# STM32U5Gx register map
File version: 1.0
CPU: CM33 r0p1, little endian, MPU, FPU, 4 interrupt priority bits
Registers are 32-bit, read-write, reset 0x0 unless marked. A register's access mark holds for its fields unless they carry their own. Offsets are from the block's base; [hi:lo] are bit positions; {n}, {i} and the like mark numbered series.

## RCC (part 3 of 4) — Reset and clock control
Base 0x46020C00
Same registers: SEC_RCC 0x56020C00
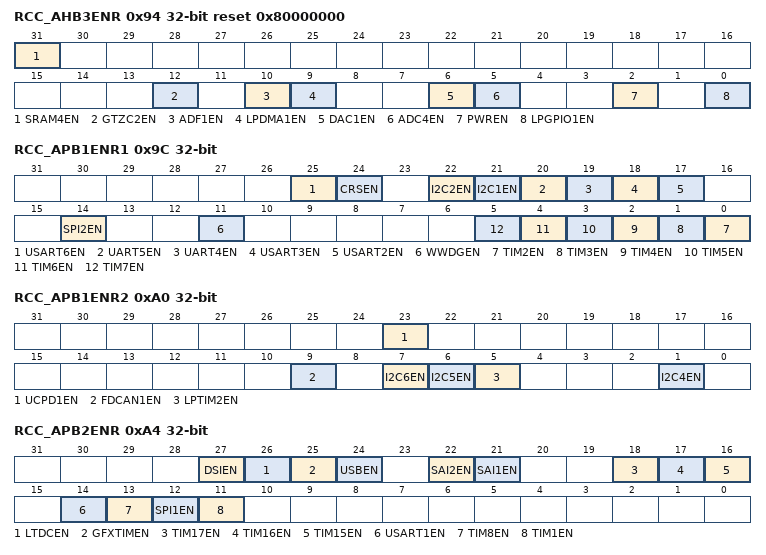
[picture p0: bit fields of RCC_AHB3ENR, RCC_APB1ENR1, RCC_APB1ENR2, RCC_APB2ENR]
0x94 RCC_AHB3ENR reset 0x80000000 — RCC AHB3 peripheral clock enable register
  [31] SRAM4EN — SRAM4 clock enable This bit is set and reset by software.
    0=SRAM4 clock disabled; 1=SRAM4 clock enabled
  [12] GTZC2EN — GTZC2 clock enable This bit is set and cleared by software.
    0=GTZC2 clock disabled; 1=GTZC2 clock enabled
  [10] ADF1EN — ADF1 clock enable This bit is set and cleared by software.
    0=ADF1 clock disabled; 1=ADF1 clock enabled
  [9] LPDMA1EN — LPDMA1 clock enable This bit is set and cleared by software.
    0=LPDMA1 clock disabled; 1=LPDMA1 clock enabled
  [6] DAC1EN — DAC1 clock enable This bit is set and cleared by software.
    0=DAC1 clock disabled; 1=DAC1 clock enabled
  [5] ADC4EN — ADC4 clock enable This bit is set and cleared by software.
    0=ADC4 clock disabled; 1=ADC4 clock enabled
  [2] PWREN — PWR clock enable This bit is set and cleared by software.
    0=PWR clock disabled; 1=PWR clock enabled
  [0] LPGPIO1EN — LPGPIO1 enable This bit is set and cleared by software.
    0=LPGPIO1 clock disabled; 1=LPGPIO1 clock enabled
0x9C RCC_APB1ENR1 — RCC APB1 peripheral clock enable register 1
  [25] USART6EN — USART6 clock enable This bit is set and cleared by software. Note: This bit is only available on some devices in the STM32U5 Series. Refer to the device datasheet for availability of its associated peripheral. If not present, consider this bit as reserved and keep it at reset value.
    0=USART6 clock disabled; 1=USART6 clock enabled
  [24] CRSEN — CRS clock enable This bit is set and cleared by software.
    0=CRS clock disabled; 1=CRS clock enabled
  [22] I2C2EN — I2C2 clock enable This bit is set and cleared by software.
    0=I2C2 clock disabled; 1=I2C2 clock enabled
  [21] I2C1EN — I2C1 clock enable This bit is set and cleared by software.
    0=I2C1 clock disabled; 1=I2C1 clock enabled
  [20] UART5EN — UART5 clock enable This bit is set and cleared by software.
    0=UART5 clock disabled; 1=UART5 clock enabled
  [19] UART4EN — UART4 clock enable This bit is set and cleared by software.
    0=UART4 clock disabled; 1=UART4 clock enabled
  [18] USART3EN — USART3 clock enable This bit is set and cleared by software.
    0=USART3 clock disabled; 1=USART3 clock enabled
  [17] USART2EN — USART2 clock enable This bit is set and cleared by software. Note: This bit is only available on some devices in the STM32U5 Series. Refer to the device datasheet for availability of its associated peripheral. If not present, consider this bit as reserved and keep it at reset value.
    0=USART2 clock disabled; 1=USART2 clock enabled
  [14] SPI2EN — SPI2 clock enable This bit is set and cleared by software.
    0=SPI2 clock disabled; 1=SPI2 clock enabled
  [11] WWDGEN — WWDG clock enable This bit is set by software to enable the window watchdog clock. It is reset by hardware system reset. This bit can also be set by hardware if the WWDG_SW option bit is reset.
    0=WWDG clock disabled; 1=WWDG clock enabled
  [n-2] TIM{n}EN (n=2..7) — TIM{n} clock enable This bit is set and cleared by software.
    0=TIM{n} clock disabled; 1=TIM{n} clock enabled
0xA0 RCC_APB1ENR2 — RCC APB1 peripheral clock enable register 2
  [23] UCPD1EN — UCPD1 clock enable This bit is set and cleared by software. Note: This bit is only available on some devices in the STM32U5 Series. Refer to the device datasheet for availability of its associated peripheral. If not present, consider this bit as reserved and keep it at reset value.
    0=UCPD1 clock disabled; 1=UCPD1 clock enabled
  [9] FDCAN1EN — FDCAN1 clock enable This bit is set and cleared by software.
    0=FDCAN1 clock disabled; 1=FDCAN1 clock enabled
  [7] I2C6EN — I2C6 clock enable This bit is set and cleared by software. Note: This bit is only available on some devices in the STM32U5 Series. Refer to the device datasheet for availability of its associated peripheral. If not present, consider this bit as reserved and keep it at reset value.
    0=I2C6 clock disabled; 1=I2C6 clock enabled
  [6] I2C5EN — I2C5 clock enable This bit is set and cleared by software. Note: This bit is only available on some devices in the STM32U5 Series. Refer to the device datasheet for availability of its associated peripheral. If not present, consider this bit as reserved and keep it at reset value.
    0=I2C5 clock disabled; 1=I2C5 clock enabled
  [5] LPTIM2EN — LPTIM2 clock enable This bit is set and cleared by software.
    0=LPTIM2 clock disabled; 1=LPTIM2 clock enabled
  [1] I2C4EN — I2C4 clock enable This bit is set and cleared by software
    0=I2C4 clock disabled; 1=I2C4 clock enabled
0xA4 RCC_APB2ENR — RCC APB2 peripheral clock enable register
  [27] DSIEN — DSI clock enable This bit is set and cleared by software. Note: This bit is only available on some devices in the STM32U5 Series. Refer to the device datasheet for availability of its associated peripheral. If not present, consider this bit as reserved and keep it at reset value.
    0=DSI clock disabled; 1=DSI clock enabled
  [26] LTDCEN — LTDC clock enable This bit is set and cleared by software. Note: This bit is only available on some devices in the STM32U5 Series. Refer to the device datasheet for availability of its associated peripheral. If not present, consider this bit as reserved and keep it at reset value.
    0=LTDC clock disabled; 1=LTDC clock enabled
  [25] GFXTIMEN — GFXTIM clock enable This bit is set and cleared by software. Note: This bit is only available on some devices in the STM32U5 Series. Refer to the device datasheet for availability of its associated peripheral. If not present, consider this bit as reserved and keep it at reset value.
    0=GFXTIM clock disabled; 1=GFXTIM clock enabled
  [24] USBEN — USB clock enable This bit is set and cleared by software. Note: This bit is only available on some devices in the STM32U5 Series. Refer to the device datasheet for availability of its associated peripheral. If not present, consider this bit as reserved and keep it at reset value.
    0=USB clock disabled; 1=USB clock enabled
  [22] SAI2EN — SAI2 clock enable This bit is set and cleared by software. Note: This bit is only available on some devices in the STM32U5 Series. Refer to the device datasheet for availability of its associated peripheral. If not present, consider this bit as reserved and keep it at reset value.
    0=SAI2 clock disabled; 1=SAI2 clock enabled
  [21] SAI1EN — SAI1 clock enable This bit is set and cleared by software.
    0=SAI1 clock disabled; 1=SAI1 clock enabled
  [18] TIM17EN — TIM17 clock enable This bit is set and cleared by software.
    0=TIM17 clock disabled; 1=TIM17 clock enabled
  [17] TIM16EN — TIM16 clock enable This bit is set and cleared by software.
    0=TIM16 clock disabled; 1=TIM16 clock enabled
  [16] TIM15EN — TIM15 clock enable This bit is set and cleared by software.
    0=TIM15 clock disabled; 1=TIM15 clock enabled
  [14] USART1EN — USART1clock enable This bit is set and cleared by software.
    0=USART1 clock disabled; 1=USART1 clock enabled
  [13] TIM8EN — TIM8 clock enable This bit is set and cleared by software.
    0=TIM8 clock disabled; 1=TIM8 clock enabled
  [12] SPI1EN — SPI1 clock enable This bit is set and cleared by software.
    0=SPI1 clock disabled; 1=SPI1 clock enabled
  [11] TIM1EN — TIM1 clock enable This bit is set and cleared by software.
    0=TIM1 clock disabled; 1=TIM1 clock enabled
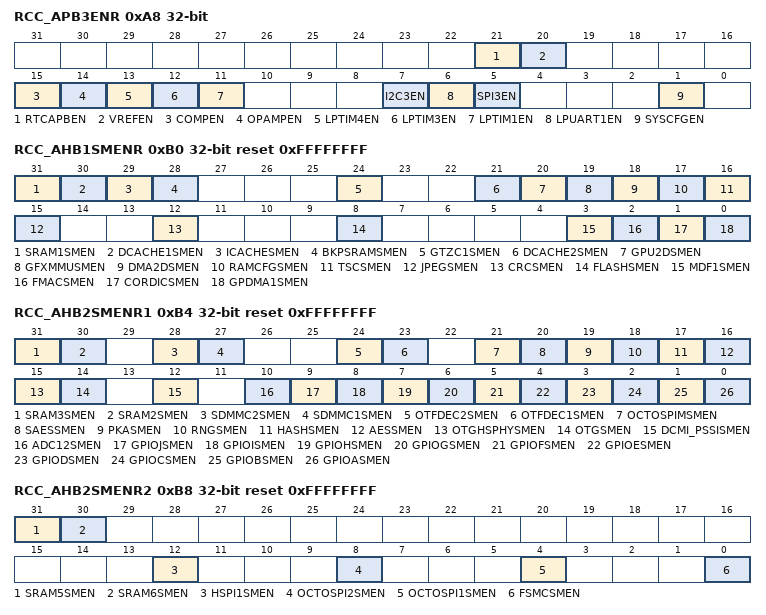
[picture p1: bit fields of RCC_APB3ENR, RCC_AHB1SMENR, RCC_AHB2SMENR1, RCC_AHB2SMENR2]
0xA8 RCC_APB3ENR — RCC APB3 peripheral clock enable register
  [21] RTCAPBEN — RTC and TAMP APB clock enable This bit is set and cleared by software.
    0=RTC and TAMP APB clock disabled; 1=RTC and TAMP APB clock enabled
  [20] VREFEN — VREFBUF clock enable This bit is set and cleared by software.
    0=VREFBUF clock disabled; 1=VREFBUF clock enabled
  [15] COMPEN — COMP clock enable This bit is set and cleared by software.
    0=COMP clock disabled; 1=COMP clock enabled
  [14] OPAMPEN — OPAMP clock enable This bit is set and cleared by software.
    0=OPAMP clock disabled; 1=OPAMP clock enabled
  [13] LPTIM4EN — LPTIM4 clock enable This bit is set and cleared by software.
    0=LPTIM4 clock disabled; 1=LPTIM4 clock enabled
  [12] LPTIM3EN — LPTIM3 clock enable This bit is set and cleared by software.
    0=LPTIM3 clock disabled; 1=LPTIM3 clock enabled
  [11] LPTIM1EN — LPTIM1 clock enable This bit is set and cleared by software.
    0=LPTIM1 clock disabled; 1=LPTIM1 clock enabled
  [7] I2C3EN — I2C3 clock enable This bit is set and cleared by software.
    0=I2C3 clock disabled; 1=I2C3 clock enabled
  [6] LPUART1EN — LPUART1 clock enable This bit is set and cleared by software.
    0=LPUART1 clock disabled; 1=LPUART1 clock enabled
  [5] SPI3EN — SPI3 clock enable This bit is set and cleared by software.
    0=SPI3 clock disabled; 1=SPI3 clock enabled
  [1] SYSCFGEN — SYSCFG clock enable This bit is set and cleared by software.
    0=SYSCFG clock disabled; 1=SYSCFG clock enabled
0xB0 RCC_AHB1SMENR reset 0xFFFFFFFF — RCC AHB1 peripheral clock enable in Sleep and Stop modes register
  [31] SRAM1SMEN — SRAM1 clock enable during Sleep and Stop modes This bit is set and cleared by software.
    0=SRAM1 clocks disabled by the clock gating during Sleep and Stop modes; 1=SRAM1 clocks enabled by the clock gating during Sleep and Stop modes
  [30] DCACHE1SMEN — DCACHE1 clock enable during Sleep and Stop modes This bit is set and cleared by software.
    0=DCACHE1 clocks disabled by the clock gating during Sleep and Stop modes; 1=DCACHE1 clocks enabled by the clock gating during Sleep and Stop modes
  [29] ICACHESMEN — ICACHE clock enable during Sleep and Stop modes This bit is set and cleared by software.
    0=ICACHE clocks disabled by the clock gating during Sleep and Stop modes; 1=ICACHE clocks enabled by the clock gating during Sleep and Stop modes
  [28] BKPSRAMSMEN — BKPSRAM clock enable during Sleep and Stop modes This bit is set and cleared by software
    0=BKPSRAM clocks disabled by the clock gating during Sleep and Stop modes; 1=BKPSRAM clocks enabled by the clock gating during Sleep and Stop modes
  [24] GTZC1SMEN — GTZC1 clock enable during Sleep and Stop modes This bit is set and cleared by software.
    0=GTZC1 clocks disabled by the clock gating during Sleep and Stop modes; 1=GTZC1 clocks enabled by the clock gating during Sleep and Stop modes
  [21] DCACHE2SMEN — DCACHE2 clock enable during Sleep and Stop modes This bit is set and cleared by software. Note: This bit is only available on some devices in the STM32U5 Series. Refer to the device datasheet for availability of its associated peripheral. If not present, consider this bit as reserved and keep it at reset value.
    0=DCACHE2 clocks disabled by the clock gating during Sleep and Stop modes; 1=DCACHE2 clocks enabled by the clock gating during Sleep and Stop modes
  [20] GPU2DSMEN — GPU2D clock enable during Sleep and Stop modes This bit is set and cleared by software. Note: This bit is only available on some devices in the STM32U5 Series. Refer to the device datasheet for availability of its associated peripheral. If not present, consider this bit as reserved and keep it at reset value.
    0=GPU2D clocks disabled by the clock gating during Sleep and Stop modes; 1=GPU2D clocks enabled by the clock gating during Sleep and Stop modes
  [19] GFXMMUSMEN — GFXMMU clock enable during Sleep and Stop modes This bit is set and cleared by software. Note: This bit is only available on some devices in the STM32U5 Series. Refer to the device datasheet for availability of its associated peripheral. If not present, consider this bit as reserved and keep it at reset value.
    0=GFXMMU clocks disabled by the clock gating during Sleep and Stop modes; 1=GFXMMU clocks enabled by the clock gating during Sleep and Stop modes
  [18] DMA2DSMEN — DMA2D clock enable during Sleep and Stop modes This bit is set and cleared by software. Note: This bit is only available on some devices in the STM32U5 Series. Refer to the device datasheet for availability of its associated peripheral. If not present, consider this bit as reserved and keep it at reset value.
    0=DMA2D clocks disabled by the clock gating during Sleep and Stop modes; 1=DMA2D clocks enabled by the clock gating during Sleep and Stop modes
  [17] RAMCFGSMEN — RAMCFG clock enable during Sleep and Stop modes This bit is set and cleared by software.
    0=RAMCFG clocks disabled by the clock gating during Sleep and Stop modes; 1=RAMCFG clocks enabled by the clock gating during Sleep and Stop modes
  [16] TSCSMEN — TSC clocks enable during Sleep and Stop modes This bit is set and cleared by software.
    0=TSC clocks disabled by the clock gating during Sleep and Stop modes; 1=TSC clocks enabled by the clock gating during Sleep and Stop modes
  [15] JPEGSMEN — JPEG clocks enable during Sleep and Stop modes This bit is set and cleared by software. Note: This bit is only available on some devices in the STM32U5 Series. Refer to the device datasheet for availability of its associated peripheral. If not present, consider this bit as reserved and keep it at reset value.
    0=JPEG clocks disabled by the clock gating during Sleep and Stop modes; 1=JPEG clocks enabled by the clock gating during Sleep and Stop modes
  [12] CRCSMEN — CRC clocks enable during Sleep and Stop modes This bit is set and cleared by software.
    0=CRC clocks disabled by the clock gating during Sleep and Stop modes; 1=CRC clocks enabled by the clock gating during Sleep and Stop modes
  [8] FLASHSMEN — FLASH clocks enable during Sleep and Stop modes This bit is set and cleared by software.
    0=FLASH clocks disabled by the clock gating during Sleep and Stop modes; 1=FLASH clocks enabled by the clock gating during Sleep and Stop modes
  [3] MDF1SMEN — MDF1 clocks enable during Sleep and Stop modes. This bit is set and cleared by software. Note: This bit must be set to allow the peripheral to wake up from Stop modes.
    0=MDF1 clocks disabled by the clock gating during Sleep and Stop modes; 1=MDF1 clocks enabled by the clock gating during Sleep and Stop modes
  [2] FMACSMEN — FMAC clocks enable during Sleep and Stop modes. This bit is set and cleared by software.
    0=FMAC clocks disabled by the clock gating during Sleep and Stop modes; 1=FMAC clocks enabled by the clock gating during Sleep and Stop modes
  [1] CORDICSMEN — CORDIC clocks enable during Sleep and Stop modes This bit is set and cleared by software during Sleep mode.
    0=CORDIC clocks disabled by the clock gating during Sleep and Stop modes; 1=CORDIC clocks enabled by the clock gating during Sleep and Stop modes
  [0] GPDMA1SMEN — GPDMA1 clocks enable during Sleep and Stop modes This bit is set and cleared by software. Note: This bit must be set to allow the peripheral to wake up from Stop modes.
    0=GPDMA1 clocks disabled by the clock gating during Sleep and Stop modes; 1=GPDMA1 clocks enabled by the clock gating during Sleep and Stop modes
0xB4 RCC_AHB2SMENR1 reset 0xFFFFFFFF — RCC AHB2 peripheral clock enable in Sleep and Stop modes register 1
  [31] SRAM3SMEN — SRAM3 clock enable during Sleep and Stop modes This bit is set and cleared by software. Note: This bit is only available on some devices in the STM32U5 Series. Refer to the device datasheet for availability of its associated peripheral. If not present, consider this bit as reserved and keep it at reset value.
    0=SRAM3 clocks disabled by the clock gating during Sleep and Stop modes; 1=SRAM3 clocks enabled by the clock gating during Sleep and Stop modes
  [30] SRAM2SMEN — SRAM2 clock enable during Sleep and Stop modes This bit is set and cleared by software.
    0=SRAM2 clocks disabled by the clock gating during Sleep and Stop modes; 1=SRAM2 clocks enabled by the clock gating during Sleep and Stop modes
  [28] SDMMC2SMEN — SDMMC2 clock enable during Sleep and Stop modes This bit is set and cleared by software. Note: This bit is only available on some devices in the STM32U5 Series. Refer to the device datasheet for availability of its associated peripheral. If not present, consider this bit as reserved and keep it at reset value.
    0=SDMMC2 clocks disabled by the clock gating during Sleep and Stop modes; 1=SDMMC2 clocks enabled by the clock gating during Sleep and Stop modes
  [27] SDMMC1SMEN — SDMMC1 clock enable during Sleep and Stop modes This bit is set and cleared by software.
    0=SDMMC1 clocks disabled by the clock gating during Sleep and Stop modes; 1=SDMMC1 clocks enabled by the clock gating during Sleep and Stop modes
  [24] OTFDEC2SMEN — OTFDEC2 clock enable during Sleep and Stop modes This bit is set and cleared by software. Note: This bit is only available on some devices in the STM32U5 Series. Refer to the device datasheet for availability of its associated peripheral. If not present, consider this bit as reserved and keep it at reset value.
    0=OTFDEC2 clocks disabled by the clock gating during Sleep and Stop modes; 1=OTFDEC2 clocks enabled by the clock gating during Sleep and Stop modes
  [23] OTFDEC1SMEN — OTFDEC1 clock enable during Sleep and Stop modes This bit is set and cleared by software. Note: This bit is only available on some devices in the STM32U5 Series. Refer to the device datasheet for availability of its associated peripheral. If not present, consider this bit as reserved and keep it at reset value.
    0=OTFDEC1 clocks disabled by the clock gating during Sleep and Stop modes; 1=OTFDEC1 clocks enabled by the clock gating during Sleep and Stop modes
  [21] OCTOSPIMSMEN — OCTOSPIM clock enable during Sleep and Stop modes This bit is set and cleared by software. Note: This bit is only available on some devices in the STM32U5 Series. Refer to the device datasheet for availability of its associated peripheral. If not present, consider this bit as reserved and keep it at reset value.
    0=OCTOSPIM clocks disabled by the clock gating during Sleep and Stop modes; 1=OCTOSPIM clocks enabled by the clock gating during Sleep and Stop modes
  [20] SAESSMEN — SAES accelerator clock enable during Sleep and Stop modes This bit is set and cleared by software. Note: This bit is only available on some devices in the STM32U5 Series. Refer to the device datasheet for availability of its associated peripheral. If not present, consider this bit as reserved and keep it at reset value.
    0=SAES clocks disabled by the clock gating during Sleep and Stop modes; 1=SAES clocks enabled by the clock gating during Sleep and Stop modes
  [19] PKASMEN — PKA clock enable during Sleep and Stop modes This bit is set and cleared by software. Note: This bit is only available on some devices in the STM32U5 Series. Refer to the device datasheet for availability of its associated peripheral. If not present, consider this bit as reserved and keep it at reset value.
    0=PKA clocks disabled by the clock gating during Sleep and Stop modes; 1=PKA clocks enabled by the clock gating during Sleep and Stop modes
  [18] RNGSMEN — RNG clock enable during Sleep and Stop modes This bit is set and cleared by software.
    0=RNG clocks disabled by the clock gating during Sleep and Stop modes; 1=RNG clocks enabled by the clock gating during Sleep and Stop modes
  [17] HASHSMEN — HASH clock enable during Sleep and Stop modes This bit is set and cleared by software
    0=HASH clocks disabled by the clock gating during Sleep and Stop modes; 1=HASH clocks enabled by the clock gating during Sleep and Stop modes
  [16] AESSMEN — AES clock enable during Sleep and Stop modes This bit is set and cleared by software Note: This bit is only available on some devices in the STM32U5 Series. Refer to the device datasheet for availability of its associated peripheral. If not present, consider this bit as reserved and keep it at reset value.
    0=AES clocks disabled by the clock gating during Sleep and Stop modes; 1=AES clocks enabled by the clock gating during Sleep and Stop modes
  [15] OTGHSPHYSMEN — OTG_HS PHY clock enable during Sleep and Stop modes This bit is set and cleared by software Note: This bit is only available on some devices in the STM32U5 Series. Refer to the device datasheet for availability of its associated peripheral. If not present, consider this bit as reserved and keep it at reset value.
    0=OTG_HS PHY clocks disabled by the clock gating during Sleep and Stop modes; 1=OTG_HS PHY clocks enabled by the clock gating during Sleep and Stop modes
  [14] OTGSMEN — OTG_FS and OTG_HS clocks enable during Sleep and Stop modes This bit is set and cleared by software. Note: This bit is only available on some devices in the STM32U5 Series. Refer to the device datasheet for availability of its associated peripheral. If not present, consider this bit as reserved and keep it at reset value.
    0=OTG_FS and OTG_HS clocks disabled by the clock gating during Sleep and Stop modes; 1=OTG_FS and OTG_HS clocks enabled by the clock gating during Sleep and Stop modes
  [12] DCMI_PSSISMEN — DCMI and PSSI clock enable during Sleep and Stop modes This bit is set and cleared by software.
    0=DCMI and PSSI clocks disabled by the clock gating during Sleep and Stop modes; 1=DCMI and PSSI clocks enabled by the clock gating during Sleep and Stop modes
  [10] ADC12SMEN — ADC1 and ADC2 clock enable during Sleep and Stop modes This bit is set and cleared by software. Note: This bit impacts ADC1 in STM32U535/545/575/585 and ADC1/ADC2 in�STM32U59x/5Ax/5Fx/5Gx.
    0=ADC1 and ADC2 clocks disabled by the clock gating during Sleep and Stop modes; 1=ADC1 and ADC2 clocks enabled by the clock gating during Sleep and Stop modes
  [9] GPIOJSMEN — I/O port J clock enable during Sleep and Stop modes This bit is set and cleared by software. Note: This bit is only available on some devices in the STM32U5 Series. Refer to the device datasheet for availability of its associated peripheral. If not present, consider this bit as reserved and keep it at reset value.
    0=I/O port J clocks disabled by the clock gating during Sleep and Stop modes; 1=I/O port J clocks enabled by the clock gating during Sleep and Stop modes
  [8] GPIOISMEN — I/O port I clocks enable during Sleep and Stop modes This bit is set and cleared by software. Note: This bit is only available on some devices in the STM32U5 Series. Refer to the device datasheet for availability of its associated peripheral. If not present, consider this bit as reserved and keep it at reset value.
    0=I/O port I clocks disabled by the clock gating during Sleep and Stop modes; 1=I/O port I clocks enabled by the clock gating during Sleep and Stop modes
  [7] GPIOHSMEN — I/O port H clocks enable during Sleep and Stop modes This bit is set and cleared by software.
    0=I/O port H clocks disabled by the clock gating during Sleep and Stop modes; 1=I/O port H clocks enabled by the clock gating during Sleep and Stop modes
  [6] GPIOGSMEN — I/O port G clocks enable during Sleep and Stop modes This bit is set and cleared by software.
    0=I/O port G clocks disabled by the clock gating during Sleep and Stop modes; 1=I/O port G clocks enabled by the clock gating during Sleep and Stop modes
  [5] GPIOFSMEN — I/O port F clocks enable during Sleep and Stop modes This bit is set and cleared by software. Note: This bit is only available on some devices in the STM32U5 Series. Refer to the device datasheet for availability of its associated peripheral. If not present, consider this bit as reserved and keep it at reset value.
    0=I/O port F clocks disabled by the clock gating during Sleep and Stop modes; 1=I/O port F clocks enabled by the clock gating during Sleep and Stop modes
  [4] GPIOESMEN — I/O port E clocks enable during Sleep and Stop modes This bit is set and cleared by software.
    0=I/O port E clocks disabled by the clock gating during Sleep and Stop modes; 1=I/O port E clocks enabled by the clock gating during Sleep and Stop modes
  [3] GPIODSMEN — I/O port D clocks enable during Sleep and Stop modes This bit is set and cleared by software.
    0=I/O port D clocks disabled by the clock gating during Sleep and Stop modes; 1=I/O port D clocks enabled by the clock gating during Sleep and Stop modes
  [2] GPIOCSMEN — I/O port C clocks enable during Sleep and Stop modes This bit is set and cleared by software.
    0=I/O port C clocks disabled by the clock gating during Sleep and Stop modes; 1=I/O port C clocks enabled by the clock gating during Sleep and Stop modes
  [1] GPIOBSMEN — I/O port B clocks enable during Sleep and Stop modes This bit is set and cleared by software.
    0=I/O port B clocks disabled by the clock gating during Sleep and Stop modes; 1=I/O port B clocks enabled by the clock gating during Sleep and Stop modes
  [0] GPIOASMEN — I/O port A clocks enable during Sleep and Stop modes This bit is set and cleared by software.
    0=I/O port A clocks disabled by the clock gating during Sleep and Stop modes; 1=I/O port A clocks enabled by the clock gating during Sleep and Stop modes
0xB8 RCC_AHB2SMENR2 reset 0xFFFFFFFF — RCC AHB2 peripheral clock enable in Sleep and Stop modes register 2
  [31] SRAM5SMEN — SRAM5 clock enable during Sleep and Stop modes This bit is set and cleared by software. Note: This bit is only available on some devices in the STM32U5 Series. Refer to the device datasheet for availability of its associated peripheral. If not present, consider this bit as reserved and keep it at reset value.
    0=SRAM5 clocks disabled by the clock gating during Sleep and Stop modes; 1=SRAM5 clocks enabled by the clock gating during Sleep and Stop modes
  [30] SRAM6SMEN — SRAM6 clock enable during Sleep and Stop modes This bit is set and cleared by software. Note: This bit is only available on some devices in the STM32U5 Series. Refer to the device datasheet for availability of its associated peripheral. If not present, consider this bit as reserved and keep it at reset value.
    0=SRAM6 clocks disabled by the clock gating during Sleep and Stop modes; 1=SRAM6 clocks enabled by the clock gating during Sleep and Stop modes
  [12] HSPI1SMEN — HSPI1 clock enable during Sleep and Stop modes This bit is set and cleared by software. Note: This bit is only available on some devices in the STM32U5 Series. Refer to the device datasheet for availability of its associated peripheral. If not present, consider this bit as reserved and keep it at reset value.
    0=HSPI1 clocks disabled by the clock gating during Sleep and Stop modes; 1=HSP1I clocks enabled by the clock gating during Sleep and Stop modes
  [8] OCTOSPI2SMEN — OCTOSPI2 clock enable during Sleep and Stop modes This bit is set and cleared by software. Note: This bit is only available on some devices in the STM32U5 Series. Refer to the device datasheet for availability of its associated peripheral. If not present, consider this bit as reserved and keep it at reset value.
    0=OCTOSPI2 clocks disabled by the clock gating during Sleep and Stop modes; 1=OCTOSPI2 clocks enabled by the clock gating during Sleep and Stop modes
  [4] OCTOSPI1SMEN — OCTOSPI1 clock enable during Sleep and Stop modes This bit is set and cleared by software.
    0=OCTOSPI1 clocks disabled by the clock gating during Sleep and Stop modes; 1=OCTOSPI1 clocks enabled by the clock gating during Sleep and Stop modes
  [0] FSMCSMEN — FSMC clock enable during Sleep and Stop modes This bit is set and cleared by software. Note: This bit is only available on some devices in the STM32U5 Series. Refer to the device datasheet for availability of its associated peripheral. If not present, consider this bit as reserved and keep it at reset value.
    0=FSMC clocks disabled by the clock gating during Sleep and Stop modes; 1=FSMC clocks enabled by the clock gating during Sleep and Stop modes
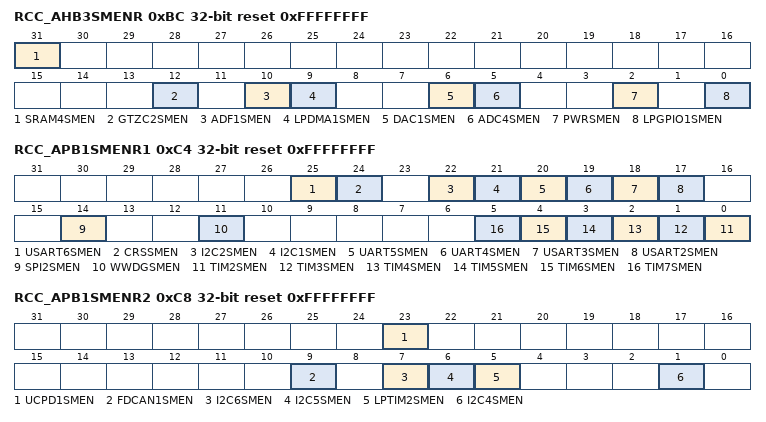
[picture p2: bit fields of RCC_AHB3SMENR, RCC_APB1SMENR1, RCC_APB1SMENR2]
0xBC RCC_AHB3SMENR reset 0xFFFFFFFF — RCC AHB3 peripheral clock enable in Sleep and Stop modes register
  [31] SRAM4SMEN — SRAM4 clock enable during Sleep and Stop modes This bit is set and cleared by software.
    0=SRAM4 clocks disabled by the clock gating during Sleep and Stop modes; 1=SRAM4 clocks enabled by the clock gating during Sleep and Stop modes
  [12] GTZC2SMEN — GTZC2 clock enable during Sleep and Stop modes This bit is set and cleared by software.
    0=GTZC2 clock disabled by the clock gating during Sleep and Stop modes; 1=GTZC2 clock enabled by the clock gating during Sleep and Stop modes
  [10] ADF1SMEN — ADF1 clock enable during Sleep and Stop modes This bit is set and cleared by software. Note: This bit must be set to allow the peripheral to wake up from Stop modes.
    0=ADF1 clock disabled by the clock gating during Sleep and Stop modes; 1=ADF1 clock enabled by the clock gating during Sleep and Stop modes
  [9] LPDMA1SMEN — LPDMA1 clock enable during Sleep and Stop modes This bit is set and cleared by software. Note: This bit must be set to allow the peripheral to wake up from Stop modes.
    0=LPDMA1 clock disabled by the clock gating during Sleep and Stop modes; 1=LPDMA1 clock enabled by the clock gating during Sleep and Stop modes
  [6] DAC1SMEN — DAC1 clock enable during Sleep and Stop modes This bit is set and cleared by software. Note: This bit must be set to allow the peripheral to wake up from Stop modes.
    0=DAC1 clock disabled by the clock gating during Sleep and Stop modes; 1=DAC1 clock enabled by the clock gating during Sleep and Stop modes
  [5] ADC4SMEN — ADC4 clock enable during Sleep and Stop modes This bit is set and cleared by software. Note: This bit must be set to allow the peripheral to wake up from Stop modes.
    0=ADC4 clock disabled by the clock gating during Sleep and Stop modes; 1=ADC4 clock enabled by the clock gating during Sleep and Stop modes
  [2] PWRSMEN — PWR clock enable during Sleep and Stop modes This bit is set and cleared by software.
    0=PWR clock disabled by the clock gating during Sleep and Stop modes; 1=PWR clock enabled by the clock gating during Sleep and Stop modes
  [0] LPGPIO1SMEN — LPGPIO1 enable during Sleep and Stop modes This bit is set and cleared by software.
    0=LPGPIO1 clock disabled by the clock gating during Sleep and Stop modes; 1=LPGPIO1 clock enabled by the clock gating during Sleep and Stop modes
0xC4 RCC_APB1SMENR1 reset 0xFFFFFFFF — RCC APB1 peripheral clock enable in Sleep and Stop modes register 1
  [25] USART6SMEN — USART6 clock enable during Sleep and Stop modes This bit is set and cleared by software. Note: This bit must be set to allow the peripheral to wake up from Stop modes. Note: This bit is only available on some devices in the STM32U5 Series. Refer to the device datasheet for availability of its associated peripheral. If not present, consider this bit as reserved and keep it at reset value.
    0=USART6 clocks disabled by the clock gating during Sleep and Stop modes; 1=USART6 clocks enabled by the clock gating during Sleep and Stop modes
  [24] CRSSMEN — CRS clock enable during Sleep and Stop modes This bit is set and cleared by software.
    0=CRS clocks disabled by the clock gating during Sleep and Stop modes; 1=CRS clocks enabled by the clock gating during Sleep and Stop modes
  [22] I2C2SMEN — I2C2 clock enable during Sleep and Stop modes This bit is set and cleared by software. Note: This bit must be set to allow the peripheral to wake up from Stop modes.
    0=I2C2 clocks disabled by the clock gating during Sleep and Stop modes; 1=I2C2 clocks enabled by the clock gating during Sleep and Stop modes
  [21] I2C1SMEN — I2C1 clock enable during Sleep and Stop modes This bit is set and cleared by software. Note: This bit must be set to allow the peripheral to wake up from Stop modes.
    0=I2C1 clocks disabled by the clock gating during Sleep and Stop modes; 1=I2C1 clocks enabled by the clock gating during Sleep and Stop modes
  [20] UART5SMEN — UART5 clock enable during Sleep and Stop modes This bit is set and cleared by software. Note: This bit must be set to allow the peripheral to wake up from Stop modes.
    0=UART5 clocks disabled by the clock gating during Sleep and Stop modes; 1=UART5 clocks enabled by the clock gating during Sleep and Stop modes
  [19] UART4SMEN — UART4 clock enable during Sleep and Stop modes This bit is set and cleared by software. Note: This bit must be set to allow the peripheral to wake up from Stop modes.
    0=UART4 clocks disabled by the clock gating during Sleep and Stop modes; 1=UART4 clocks enabled by the clock gating during Sleep and Stop modes
  [18] USART3SMEN — USART3 clock enable during Sleep and Stop modes This bit is set and cleared by software. Note: This bit must be set to allow the peripheral to wake up from Stop modes.
    0=USART3 clocks disabled by the clock gating during Sleep and Stop modes; 1=USART3 clocks enabled by the clock gating during Sleep and Stop modes
  [17] USART2SMEN — USART2 clock enable during Sleep and Stop modes This bit is set and cleared by software. Note: This bit must be set to allow the peripheral to wake up from Stop modes. Note: This bit is only available on some devices in the STM32U5 Series. Refer to the device datasheet for availability of its associated peripheral. If not present, consider this bit as reserved and keep it at reset value.
    0=USART2 clocks disabled by the clock gating during Sleep and Stop modes; 1=USART2 clocks enabled by the clock gating during Sleep and Stop modes
  [14] SPI2SMEN — SPI2 clock enable during Sleep and Stop modes This bit is set and cleared by software. Note: This bit must be set to allow the peripheral to wake up from Stop modes.
    0=SPI2 clocks disabled by the clock gating during Sleep and Stop modes; 1=SPI2 clocks enabled by the clock gating during Sleep and Stop modes
  [11] WWDGSMEN — Window watchdog clock enable during Sleep and Stop modes This bit is set and cleared by software. It is forced to one by hardware when the hardware WWDG option is activated.
    0=Window watchdog clocks disabled by the clock gating during Sleep and Stop modes; 1=Window watchdog clocks enabled by the clock gating during Sleep and Stop modes
  [n-2] TIM{n}SMEN (n=2..7) — TIM{n} clock enable during Sleep and Stop modes This bit is set and cleared by software.
    0=TIM{n} clocks disabled by the clock gating during Sleep and Stop modes; 1=TIM{n} clocks enabled by the clock gating during Sleep and Stop modes
0xC8 RCC_APB1SMENR2 reset 0xFFFFFFFF — RCC APB1 peripheral clocks enable in Sleep and Stop modes register 2
  [23] UCPD1SMEN — UCPD1 clock enable during Sleep and Stop modes This bit is set and cleared by software. Note: This bit is only available on some devices in the STM32U5 Series. Refer to the device datasheet for availability of its associated peripheral. If not present, consider this bit as reserved and keep it at reset value.
    0=UCPD1 clocks disabled by the clock gating during Sleep and Stop modes; 1=UCPD1 clocks enabled by the clock gating during Sleep and Stop modes
  [9] FDCAN1SMEN — FDCAN1 clock enable during Sleep and Stop modes This bit is set and cleared by software.
    0=FDCAN1 clocks disabled by the clock gating during Sleep and Stop modes; 1=FDCAN1 clocks enabled by the clock gating during Sleep and Stop modes
  [7] I2C6SMEN — I2C6 clock enable during Sleep and Stop modes This bit is set and cleared by software Note: This bit must be set to allow the peripheral to wake up from Stop modes. Note: This bit is only available on some devices in the STM32U5 Series. Refer to the device datasheet for availability of its associated peripheral. If not present, consider this bit as reserved and keep it at reset value.
    0=I2C6 clocks disabled by the clock gating during Sleep and Stop modes; 1=I2C6 clocks enabled by the clock gating during Sleep and Stop modes
  [6] I2C5SMEN — I2C5 clock enable during Sleep and Stop modes This bit is set and cleared by software Note: This bit must be set to allow the peripheral to wake up from Stop modes. Note: This bit is only available on some devices in the STM32U5 Series. Refer to the device datasheet for availability of its associated peripheral. If not present, consider this bit as reserved and keep it at reset value.
    0=I2C5 clocks disabled by the clock gating during Sleep and Stop modes; 1=I2C5 clocks enabled by the clock gating during Sleep and Stop modes
  [5] LPTIM2SMEN — LPTIM2 clock enable during Sleep and Stop modes This bit is set and cleared by software. Note: This bit must be set to allow the peripheral to wake up from Stop modes.
    0=LPTIM2 clocks disabled by the clock gating during Sleep and Stop modes; 1=LPTIM2 clocks enabled by the clock gating during Sleep and Stop modes
  [1] I2C4SMEN — I2C4 clock enable during Sleep and Stop modes This bit is set and cleared by software Note: This bit must be set to allow the peripheral to wake up from Stop modes.
    0=I2C4 clocks disabled by the clock gating during Sleep and Stop modes; 1=I2C4 clocks enabled by the clock gating during Sleep and Stop modes
